# G32R430xx register map
Vendor: Geehy Semiconductor Co., Ltd.; Series: G32R4; File version: 1.0
CPU: CM52 r0p1, little endian, MPU, no FPU, DSP, VTOR, 4 interrupt priority bits
Registers are 32-bit, read-write, reset 0x0 unless marked. A register's access mark holds for its fields unless they carry their own. Offsets are from the block's base; [hi:lo] are bit positions; {n}, {i} and the like mark numbered series; 'fields as' and 'values as' point back to an identical list.

## DMA — DMA controller
Base 0x40020000
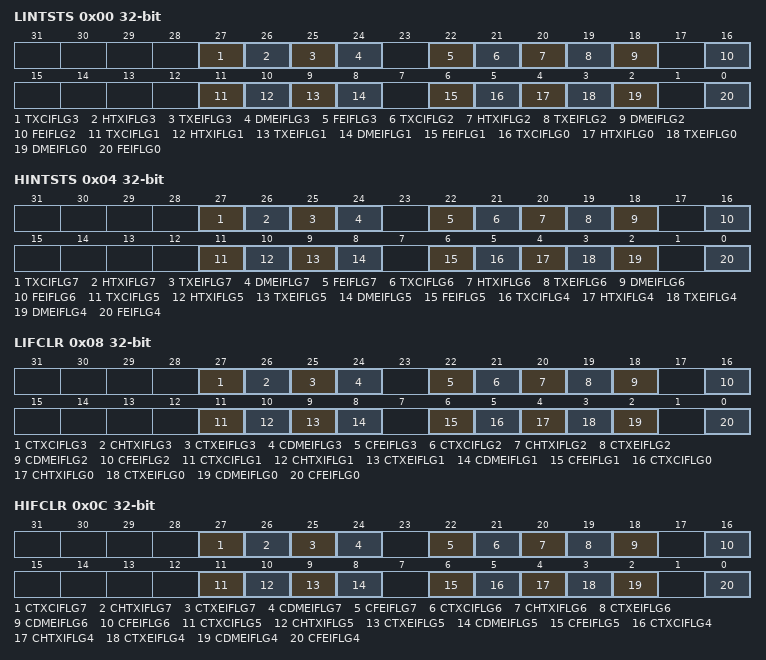
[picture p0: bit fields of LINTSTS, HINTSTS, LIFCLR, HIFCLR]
0x00 LINTSTS ro — low interrupt status register
  [27] TXCIFLG3 — Stream x transfer complete interrupt flag (x = 3..0)
  [26] HTXIFLG3 — Stream x half transfer interrupt flag (x=3..0)
  [25] TXEIFLG3 — Stream x transfer error interrupt flag (x=3..0)
  [24] DMEIFLG3 — Stream x direct mode error interrupt flag (x=3..0)
  [22] FEIFLG3 — Stream x FIFO error interrupt flag (x=3..0)
  [21] TXCIFLG2 — Stream x transfer complete interrupt flag (x = 3..0)
  [20] HTXIFLG2 — Stream x half transfer interrupt flag (x=3..0)
  [19] TXEIFLG2 — Stream x transfer error interrupt flag (x=3..0)
  [18] DMEIFLG2 — Stream x direct mode error interrupt flag (x=3..0)
  [16] FEIFLG2 — Stream x FIFO error interrupt flag (x=3..0)
  [11] TXCIFLG1 — Stream x transfer complete interrupt flag (x = 3..0)
  [10] HTXIFLG1 — Stream x half transfer interrupt flag (x=3..0)
  [9] TXEIFLG1 — Stream x transfer error interrupt flag (x=3..0)
  [8] DMEIFLG1 — Stream x direct mode error interrupt flag (x=3..0)
  [6] FEIFLG1 — Stream x FIFO error interrupt flag (x=3..0)
  [5] TXCIFLG0 — Stream x transfer complete interrupt flag (x = 3..0)
  [4] HTXIFLG0 — Stream x half transfer interrupt flag (x=3..0)
  [3] TXEIFLG0 — Stream x transfer error interrupt flag (x=3..0)
  [2] DMEIFLG0 — Stream x direct mode error interrupt flag (x=3..0)
  [0] FEIFLG0 — Stream x FIFO error interrupt flag (x=3..0)
0x04 HINTSTS ro — high interrupt status register
  [27] TXCIFLG7 — Stream x transfer complete interrupt flag (x=7..4)
  [26] HTXIFLG7 — Stream x half transfer interrupt flag (x=7..4)
  [25] TXEIFLG7 — Stream x transfer error interrupt flag (x=7..4)
  [24] DMEIFLG7 — Stream x direct mode error interrupt flag (x=7..4)
  [22] FEIFLG7 — Stream x FIFO error interrupt flag (x=7..4)
  [21] TXCIFLG6 — Stream x transfer complete interrupt flag (x=7..4)
  [20] HTXIFLG6 — Stream x half transfer interrupt flag (x=7..4)
  [19] TXEIFLG6 — Stream x transfer error interrupt flag (x=7..4)
  [18] DMEIFLG6 — Stream x direct mode error interrupt flag (x=7..4)
  [16] FEIFLG6 — Stream x FIFO error interrupt flag (x=7..4)
  [11] TXCIFLG5 — Stream x transfer complete interrupt flag (x=7..4)
  [10] HTXIFLG5 — Stream x half transfer interrupt flag (x=7..4)
  [9] TXEIFLG5 — Stream x transfer error interrupt flag (x=7..4)
  [8] DMEIFLG5 — Stream x direct mode error interrupt flag (x=7..4)
  [6] FEIFLG5 — Stream x FIFO error interrupt flag (x=7..4)
  [5] TXCIFLG4 — Stream x transfer complete interrupt flag (x=7..4)
  [4] HTXIFLG4 — Stream x half transfer interrupt flag (x=7..4)
  [3] TXEIFLG4 — Stream x transfer error interrupt flag (x=7..4)
  [2] DMEIFLG4 — Stream x direct mode error interrupt flag (x=7..4)
  [0] FEIFLG4 — Stream x FIFO error interrupt flag (x=7..4)
0x08 LIFCLR — low interrupt flag clear register
  [27] CTXCIFLG3 — Stream x clear transfer complete interrupt flag (x = 3..0)
  [26] CHTXIFLG3 — Stream x clear half transfer interrupt flag (x = 3..0)
  [25] CTXEIFLG3 — Stream x clear transfer error interrupt flag (x = 3..0)
  [24] CDMEIFLG3 — Stream x clear direct mode error interrupt flag (x = 3..0)
  [22] CFEIFLG3 — Stream x clear FIFO error interrupt flag (x = 3..0)
  [21] CTXCIFLG2 — Stream x clear transfer complete interrupt flag (x = 3..0)
  [20] CHTXIFLG2 — Stream x clear half transfer interrupt flag (x = 3..0)
  [19] CTXEIFLG2 — Stream x clear transfer error interrupt flag (x = 3..0)
  [18] CDMEIFLG2 — Stream x clear direct mode error interrupt flag (x = 3..0)
  [16] CFEIFLG2 — Stream x clear FIFO error interrupt flag (x = 3..0)
  [11] CTXCIFLG1 — Stream x clear transfer complete interrupt flag (x = 3..0)
  [10] CHTXIFLG1 — Stream x clear half transfer interrupt flag (x = 3..0)
  [9] CTXEIFLG1 — Stream x clear transfer error interrupt flag (x = 3..0)
  [8] CDMEIFLG1 — Stream x clear direct mode error interrupt flag (x = 3..0)
  [6] CFEIFLG1 — Stream x clear FIFO error interrupt flag (x = 3..0)
  [5] CTXCIFLG0 — Stream x clear transfer complete interrupt flag (x = 3..0)
  [4] CHTXIFLG0 — Stream x clear half transfer interrupt flag (x = 3..0)
  [3] CTXEIFLG0 — Stream x clear transfer error interrupt flag (x = 3..0)
  [2] CDMEIFLG0 — Stream x clear direct mode error interrupt flag (x = 3..0)
  [0] CFEIFLG0 — Stream x clear FIFO error interrupt flag (x = 3..0)
0x0C HIFCLR — high interrupt flag clear register
  [27] CTXCIFLG7 — Stream x clear transfer complete interrupt flag (x = 7..4)
  [26] CHTXIFLG7 — Stream x clear half transfer interrupt flag (x = 7..4)
  [25] CTXEIFLG7 — Stream x clear transfer error interrupt flag (x = 7..4)
  [24] CDMEIFLG7 — Stream x clear direct mode error interrupt flag (x = 7..4)
  [22] CFEIFLG7 — Stream x clear FIFO error interrupt flag (x = 7..4)
  [21] CTXCIFLG6 — Stream x clear transfer complete interrupt flag (x = 7..4)
  [20] CHTXIFLG6 — Stream x clear half transfer interrupt flag (x = 7..4)
  [19] CTXEIFLG6 — Stream x clear transfer error interrupt flag (x = 7..4)
  [18] CDMEIFLG6 — Stream x clear direct mode error interrupt flag (x = 7..4)
  [16] CFEIFLG6 — Stream x clear FIFO error interrupt flag (x = 7..4)
  [11] CTXCIFLG5 — Stream x clear transfer complete interrupt flag (x = 7..4)
  [10] CHTXIFLG5 — Stream x clear half transfer interrupt flag (x = 7..4)
  [9] CTXEIFLG5 — Stream x clear transfer error interrupt flag (x = 7..4)
  [8] CDMEIFLG5 — Stream x clear direct mode error interrupt flag (x = 7..4)
  [6] CFEIFLG5 — Stream x clear FIFO error interrupt flag (x = 7..4)
  [5] CTXCIFLG4 — Stream x clear transfer complete interrupt flag (x = 7..4)
  [4] CHTXIFLG4 — Stream x clear half transfer interrupt flag (x = 7..4)
  [3] CTXEIFLG4 — Stream x clear transfer error interrupt flag (x = 7..4)
  [2] CDMEIFLG4 — Stream x clear direct mode error interrupt flag (x = 7..4)
  [0] CFEIFLG4 — Stream x clear FIFO error interrupt flag (x = 7..4)
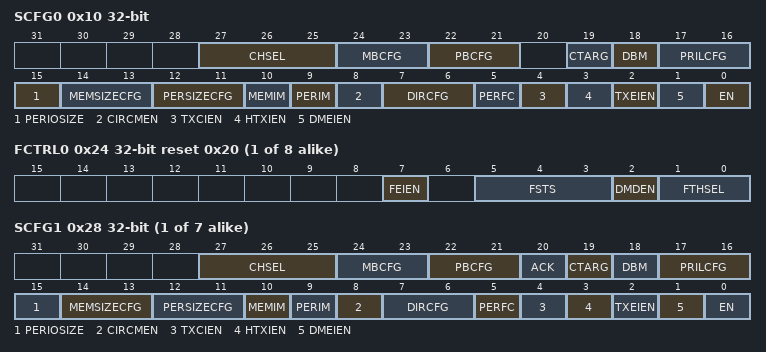
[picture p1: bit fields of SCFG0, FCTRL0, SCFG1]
0x10 SCFG0 — stream x configuration register
  [27:25] CHSEL — Channel selection
  [24:23] MBCFG — Memory burst transfer configuration
  [22:21] PBCFG — Peripheral burst transfer configuration
  [19] CTARG — Current target (only in double buffer mode)
  [18] DBM — Double buffer mode
  [17:16] PRILCFG — Priority level
  [15] PERIOSIZE — Peripheral increment offset size
  [14:13] MEMSIZECFG — Memory data size
  [12:11] PERSIZECFG — Peripheral data size
  [10] MEMIM — Memory increment mode
  [9] PERIM — Peripheral increment mode
  [8] CIRCMEN — Circular mode
  [7:6] DIRCFG — Data transfer direction
  [5] PERFC — Peripheral flow controller
  [4] TXCIEN — Transfer complete interrupt enable
  [3] HTXIEN — Half transfer interrupt enable
  [2] TXEIEN — Transfer error interrupt enable
  [1] DMEIEN — Direct mode error interrupt enable
  [0] EN — Stream enable / flag stream ready when read low
{0x14+0x18*i} NDATA{i} (i=0..7) — stream x number of data register
  [15:0] NDATA — Number of data items to transfer
{0x18+0x18*i} PADDR{i} (i=0..7) — stream x peripheral address register
  [31:0] PADDR — Peripheral address
{0x1C+0x18*i} M0ADDR{i} (i=0..4) — stream x memory 0 address register
  [31:0] M0ADDR — Memory 0 address
{0x20+0x18*i} M1ADDR{i} (i=0..4) — stream x memory 1 address register
  [31:0] M1ADDR — Memory 1 address (used in case of Double buffer mode)
{0x24+0x18*i} FCTRL{i} access per field reset 0x20 (i=0..7) — stream x FIFO control register
  [7] FEIEN rw — FIFO error interrupt enable
  [5:3] FSTS ro — FIFO status
  [2] DMDEN rw — Direct mode disable
  [1:0] FTHSEL rw — FIFO threshold selection
{0x10+0x18*i} SCFG{i} (i=1..7) — stream x configuration register
  [27:25] CHSEL — Channel selection
  [24:23] MBCFG — Memory burst transfer configuration
  [22:21] PBCFG — Peripheral burst transfer configuration
  [20] ACK
  [19] CTARG — Current target (only in double buffer mode)
  [18] DBM — Double buffer mode
  [17:16] PRILCFG — Priority level
  [15] PERIOSIZE — Peripheral increment offset size
  [14:13] MEMSIZECFG — Memory data size
  [12:11] PERSIZECFG — Peripheral data size
  [10] MEMIM — Memory increment mode
  [9] PERIM — Peripheral increment mode
  [8] CIRCMEN — Circular mode
  [7:6] DIRCFG — Data transfer direction
  [5] PERFC — Peripheral flow controller
  [4] TXCIEN — Transfer complete interrupt enable
  [3] HTXIEN — Half transfer interrupt enable
  [2] TXEIEN — Transfer error interrupt enable
  [1] DMEIEN — Direct mode error interrupt enable
  [0] EN — Stream enable / flag stream ready when read low
0x94 M1ADDR5 — stream x memory 0 address register
  [31:0] M0ADDR — Memory 0 address
0x98 S5M1AR — stream x memory 1 address register
  fields as M1ADDR0
0xAC M0ADDR6 — stream x memory 0 address register
  [31:0] M0ADDR — Memory 0 address
0xB0 M1ADDR6 — stream x memory 1 address register
  fields as M1ADDR0
0xC4 M0ADDR7 — stream x memory 0 address register
  [31:0] M0ADDR — Memory 0 address
0xC8 M1ADDR7 — stream x memory 1 address register
  fields as M1ADDR0
